# TMS320F28069 register map
Vendor: Texas Instruments; Series: C2000 F2806x; File version: 0.2.0-generated
Generated from TI CCS targetdb file f28069.xml. Review against the TI technical reference manual before production use.
Registers are 16-bit, read-write, reset 0x0 unless marked. A register's access mark holds for its fields unless they carry their own. Offsets are from the block's base; lines under a group give offsets from that group; [hi:lo] are bit positions; {n}, {i} and the like mark numbered series; 'fields as' and 'values as' point back to an identical list; <NAME> marks a mode.

## Memory map
0x00001100 DEVEMU — Dev Emu Registers
0x0000130A SYSPWRCTRL — System Power Control Registers
0x00001500 FLASH — Flash/OTP Registers
0x000015C0 CSM — Code Security Module
0x00001600 ADCRESULT — ADC Mirror Registers
0x00001800 CPUTIMER — CPU Timer Registers
0x000019C0 PIE — Peripheral Interrupt Expansion Registers
0x00001E00 FPU — Floating-Point Unit Single Precision Registers
0x00002000 DMA — DMA Registers
0x00002400 VCU — VCU Registers
0x00002800 CLA — CLA1 Registers
0x00002800 CLA0NOTVISIBLE
0x00008000 USB0 — USB Registers
0x0000A000 MCBSPA — Multi-Channel Buffered Serial Port Registers
0x0000C000 ECANA — eCAN Control and Status Registers
0x0000C080 ECANA_LAM — eCAN Local Acceptance Masks
0x0000C100 ECANA_MOTS — eCAN Message Object Time Stamps
0x0000C180 ECANA_MOTO — eCAN Message Object Time-Outs
0x0000C200 ECANA_MBX_CONTENT — eCAN Mailbox Content
0x0000C800 COMP1 — Comparator Registers
0x0000C840 COMP2 — Comparator Registers
0x0000C880 COMP3 — Comparator Registers
0x0000D000 EPWM1 — EPWM1 Registers
0x0000D080 EPWM2 — EPWMn Registers
0x0000D100 EPWM3 — EPWMn Registers
0x0000D180 EPWM4 — EPWMn Registers
0x0000D200 EPWM5 — EPWMn Registers
0x0000D280 EPWM6 — EPWMn Registers
0x0000D300 EPWM7 — EPWMn Registers
0x0000D380 EPWM8 — EPWMn Registers
0x0000D400 ECAP1 — eCAP Control and Status Registers
0x0000D440 ECAP2 — eCAP Control and Status Registers
0x0000D480 ECAP3 — eCAP Control and Status Registers
0x0000D580 HRCAP1 — HRCAP1 Registers
0x0000D5C0 HRCAP2 — HRCAP1 Registers
0x0000D600 EQEP1 — eQEP Control and Status Registers
0x0000D680 EQEP2 — eQEP Control and Status Registers
0x0000D900 HRCAP3 — HRCAP1 Registers
0x0000D940 HRCAP4 — HRCAP1 Registers
0x0000DF00 GPIO — GPIO Control Registers
0x0000E020 SYSCTRL — System Control Registers
0x0000E080 SPIA — Serial Peripheral Interface Registers
0x0000E0A0 SCIA — SCI Registers
0x0000E0C0 NMIINT — NMI Interrupt Registers
0x0000E0E0 XINT — External Interrupt Registers
0x0000E200 ADC — ADC Registers
0x0000EE80 SPIB — Serial Peripheral Interface Registers
0x0000EEA0 SCIB — SCI Registers
0x0000F200 I2CA — I2C Registers
0x007EFFF0 PWL — PWL Locations

## Further device data
tiCore=C28X, tiAddressScale=2, tiCortexDebugCompatible=false, tiProcessorName=c28x, tiGenerator=ti-c2000-toolchain

## DEVEMU — Dev Emu Registers
Base 0x00001100
0x00 DEVICECNF 32-bit — Device Configuration
0x04 CLASSID
0x06 REVID — Device ID
0x7ADB00 PARTID

## SYSPWRCTRL — System Power Control Registers
Base 0x0000130A
0x00 BORCFG — BOR Configuration

## FLASH — Flash/OTP Registers
Base 0x00001500
0x00 FOPT — Option Register
0x04 FPWR — Power Modes Register
0x06 FSTATUS — Status Register
0x08 FSTDBYWAIT — Pump/Bank Sleep to Standby Wait State Register
0x0A FACTIVEWAIT — Pump/Bank Standby to Active Wait State Register
0x0C FBANKWAIT — Bank Read Access Wait State Register
0x0E FOTPWAIT — OTP Read Access Wait State Register

## CSM — Code Security Module
Base 0x000015C0
{0x0+2i} KEY{i} (i=0..7) — CSM Key {i} Register
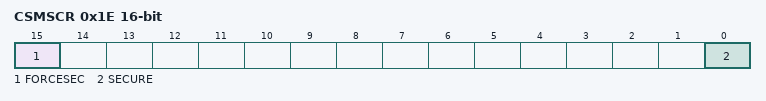
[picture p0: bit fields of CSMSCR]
0x1E CSMSCR
  [15] FORCESEC — Force Secure bit
  [0] SECURE — Secure bit

## ADCRESULT — ADC Mirror Registers
Base 0x00001600
{0x0+2i} ADCRESULT{i} (i=0..15) — Conversion Result Buffer {i}

## Licence text in the file
Generated metadata follows the license of the source TI files. Generator code is MIT licensed.
